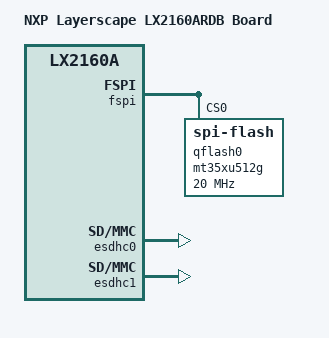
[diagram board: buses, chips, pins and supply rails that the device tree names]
/*
 * NXP LX2160ARDB device tree source
 *
 * Author:	Priyanka Jain <priyanka.jain@nxp.com>
 *		Sriram Dash <sriram.dash@nxp.com>
 *
 * Copyright 2018 NXP
 *
 * SPDX-License-Identifier:	GPL-2.0+
 */

/dts-v1/;

#include "fsl-lx2160a.dtsi"

/ {
	model = "NXP Layerscape LX2160ARDB Board";
	compatible = "fsl,lx2160ardb", "fsl,lx2160a";

	aliases {
		spi0 = &fspi;
	};

	chosen {
		stdout-path = &uart0;
	};
};

&fspi {
	bus-num = <0>;
	status = "okay";

	qflash0: mt35xu512g@0 {
		#address-cells = <1>;
		#size-cells = <1>;
		compatible = "spi-flash";
		spi-max-frequency = <20000000>; /* TODO Need to ck*/
		reg = <0>;
		/* The following setting enables 1-1-1 (CMD-ADDR-DATA) mode */
		spi-rx-bus-width = <1>; /* 1 SPI Rx lines */
		spi-tx-bus-width = <1>; /* 1 SPI Tx line */
	};

	/*
	 * MCR2[SAMEDEVICEEN] bit is enabled in FlexSPI controller for
	 * LX2160ARDB and LX2160AQDS board. Both these has same type of flash
	 * slave devices connected on both A0 and A1.
	 * No need to provide node info for second flash device.
	 */
};

&esdhc0 {
	status = "okay";
};

&esdhc1 {
	status = "okay";
};
